VERSION ""

NS_ :

BS_:

BU_: GPS_NODE DASH

BO_ 1712 GPS_Position: 8 GPS_NODE
 SG_ lat_deg : 0|32@1- (1e-07,0) [-90|90] "deg" DASH
 SG_ lon_deg : 32|32@1- (1e-07,0) [-180|180] "deg" DASH

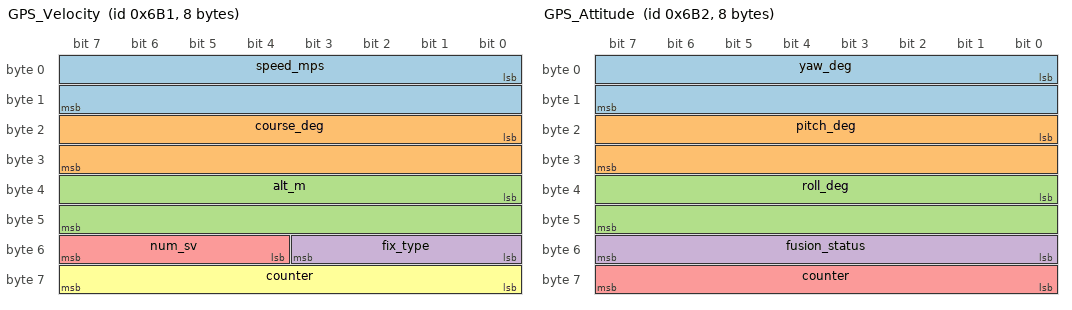
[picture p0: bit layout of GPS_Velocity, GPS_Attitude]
BO_ 1713 GPS_Velocity: 8 GPS_NODE
 SG_ speed_mps : 0|16@1+ (0.01,0) [0|655.35] "m/s" DASH
 SG_ course_deg : 16|16@1+ (0.01,0) [0|655.35] "deg" DASH
 SG_ alt_m : 32|16@1- (0.1,0) [-3276.8|3276.7] "m" DASH
 SG_ fix_type : 48|4@1+ (1,0) [0|15] "" DASH
 SG_ num_sv : 52|4@1+ (1,0) [0|15] "" DASH
 SG_ counter : 56|8@1+ (1,0) [0|255] "" DASH

BO_ 1714 GPS_Attitude: 8 GPS_NODE
 SG_ yaw_deg : 0|16@1+ (0.01,0) [0|655.35] "deg" DASH
 SG_ pitch_deg : 16|16@1- (0.01,0) [-327.68|327.67] "deg" DASH
 SG_ roll_deg : 32|16@1- (0.01,0) [-327.68|327.67] "deg" DASH
 SG_ fusion_status : 48|8@1+ (1,0) [0|255] "" DASH
 SG_ counter : 56|8@1+ (1,0) [0|255] "" DASH

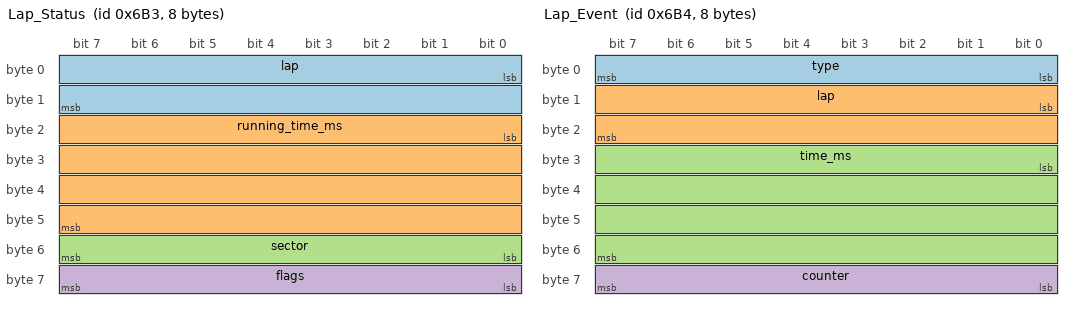
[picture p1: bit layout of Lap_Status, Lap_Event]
BO_ 1715 Lap_Status: 8 GPS_NODE
 SG_ lap : 0|16@1+ (1,0) [0|65535] "" DASH
 SG_ running_time_ms : 16|32@1+ (1,0) [0|4294967295] "ms" DASH
 SG_ sector : 48|8@1+ (1,0) [0|255] "" DASH
 SG_ flags : 56|8@1+ (1,0) [0|255] "" DASH

BO_ 1716 Lap_Event: 8 GPS_NODE
 SG_ type : 0|8@1+ (1,0) [0|255] "" DASH
 SG_ lap : 8|16@1+ (1,0) [0|65535] "" DASH
 SG_ time_ms : 24|32@1+ (1,0) [0|4294967295] "ms" DASH
 SG_ counter : 56|8@1+ (1,0) [0|255] "" DASH

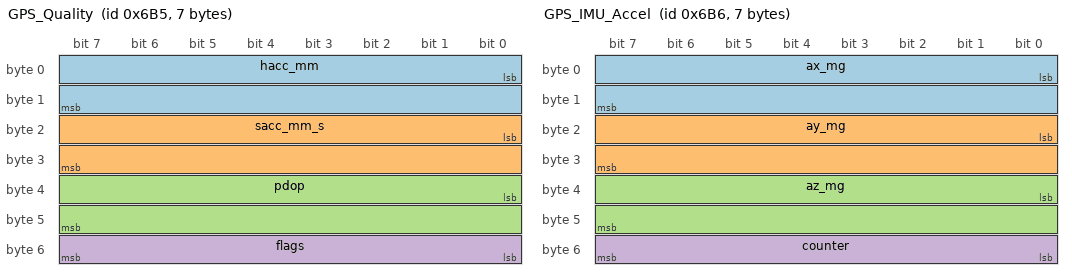
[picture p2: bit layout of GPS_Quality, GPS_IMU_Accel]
BO_ 1717 GPS_Quality: 7 GPS_NODE
 SG_ hacc_mm : 0|16@1+ (1,0) [0|65535] "mm" DASH
 SG_ sacc_mm_s : 16|16@1+ (0.1,0) [0|6553.5] "mm/s" DASH
 SG_ pdop : 32|16@1+ (0.01,0) [0|655.35] "" DASH
 SG_ flags : 48|8@1+ (1,0) [0|255] "" DASH

BO_ 1718 GPS_IMU_Accel: 7 GPS_NODE
 SG_ ax_mg : 0|16@1- (1,0) [-32768|32767] "mg" DASH
 SG_ ay_mg : 16|16@1- (1,0) [-32768|32767] "mg" DASH
 SG_ az_mg : 32|16@1- (1,0) [-32768|32767] "mg" DASH
 SG_ counter : 48|8@1+ (1,0) [0|255] "" DASH

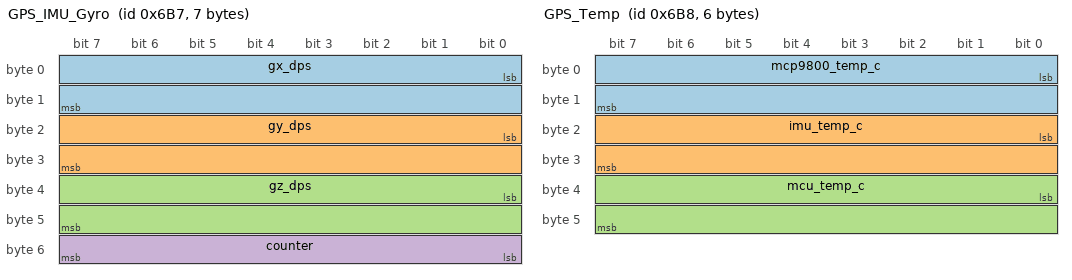
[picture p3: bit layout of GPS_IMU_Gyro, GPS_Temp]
BO_ 1719 GPS_IMU_Gyro: 7 GPS_NODE
 SG_ gx_dps : 0|16@1- (0.0625,0) [-2048|2047.94] "dps" DASH
 SG_ gy_dps : 16|16@1- (0.0625,0) [-2048|2047.94] "dps" DASH
 SG_ gz_dps : 32|16@1- (0.0625,0) [-2048|2047.94] "dps" DASH
 SG_ counter : 48|8@1+ (1,0) [0|255] "" DASH

BO_ 1720 GPS_Temp: 6 GPS_NODE
 SG_ mcp9800_temp_c : 0|16@1- (0.01,0) [-327.68|327.67] "degC" DASH
 SG_ imu_temp_c : 16|16@1- (0.01,0) [-327.68|327.67] "degC" DASH
 SG_ mcu_temp_c : 32|16@1- (0.01,0) [-327.68|327.67] "degC" DASH

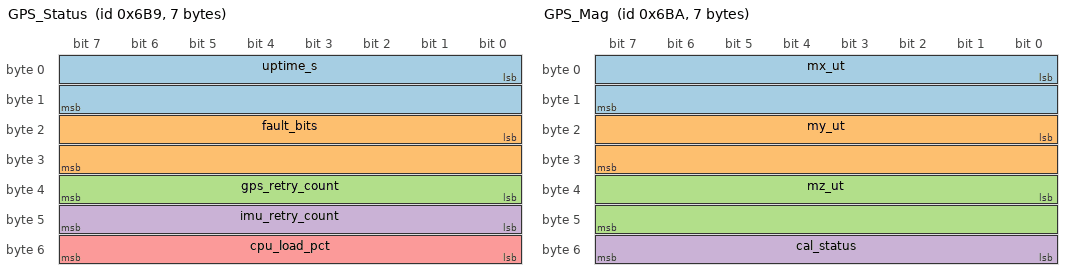
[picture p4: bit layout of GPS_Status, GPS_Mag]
BO_ 1721 GPS_Status: 7 GPS_NODE
 SG_ uptime_s : 0|16@1+ (1,0) [0|65535] "s" DASH
 SG_ fault_bits : 16|16@1+ (1,0) [0|65535] "" DASH
 SG_ gps_retry_count : 32|8@1+ (1,0) [0|255] "" DASH
 SG_ imu_retry_count : 40|8@1+ (1,0) [0|255] "" DASH
 SG_ cpu_load_pct : 48|8@1+ (1,0) [0|100] "%" DASH

BO_ 1722 GPS_Mag: 7 GPS_NODE
 SG_ mx_ut : 0|16@1- (0.1,0) [-3276.8|3276.7] "uT" DASH
 SG_ my_ut : 16|16@1- (0.1,0) [-3276.8|3276.7] "uT" DASH
 SG_ mz_ut : 32|16@1- (0.1,0) [-3276.8|3276.7] "uT" DASH
 SG_ cal_status : 48|8@1+ (1,0) [0|255] "" DASH

BO_ 1723 GPS_Frame_Origin: 8 GPS_NODE
 SG_ origin_lat_deg : 0|32@1- (1e-07,0) [-90|90] "deg" DASH
 SG_ origin_lon_deg : 32|32@1- (1e-07,0) [-180|180] "deg" DASH

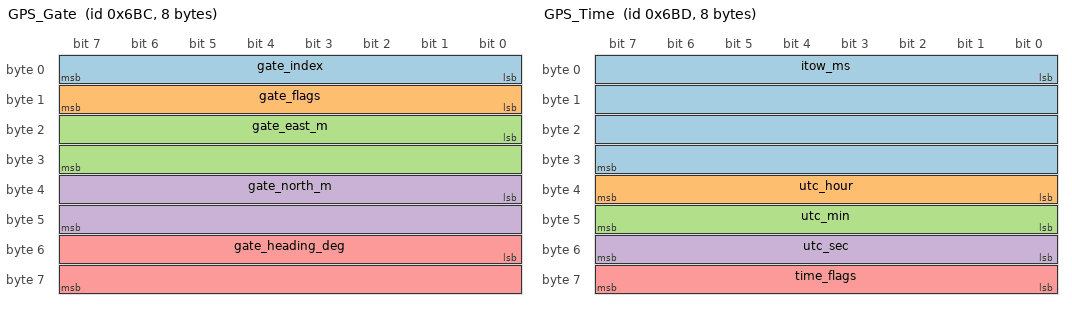
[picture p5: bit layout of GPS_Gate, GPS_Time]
BO_ 1724 GPS_Gate: 8 GPS_NODE
 SG_ gate_index : 0|8@1+ (1,0) [0|7] "" DASH
 SG_ gate_flags : 8|8@1+ (1,0) [0|255] "" DASH
 SG_ gate_east_m : 16|16@1- (0.1,0) [-3276.8|3276.7] "m" DASH
 SG_ gate_north_m : 32|16@1- (0.1,0) [-3276.8|3276.7] "m" DASH
 SG_ gate_heading_deg : 48|16@1+ (0.1,0) [0|6553.5] "deg" DASH

BO_ 1725 GPS_Time: 8 GPS_NODE
 SG_ itow_ms : 0|32@1+ (1,0) [0|604799999] "ms" DASH
 SG_ utc_hour : 32|8@1+ (1,0) [0|23] "h" DASH
 SG_ utc_min : 40|8@1+ (1,0) [0|59] "min" DASH
 SG_ utc_sec : 48|8@1+ (1,0) [0|60] "s" DASH
 SG_ time_flags : 56|8@1+ (1,0) [0|255] "" DASH

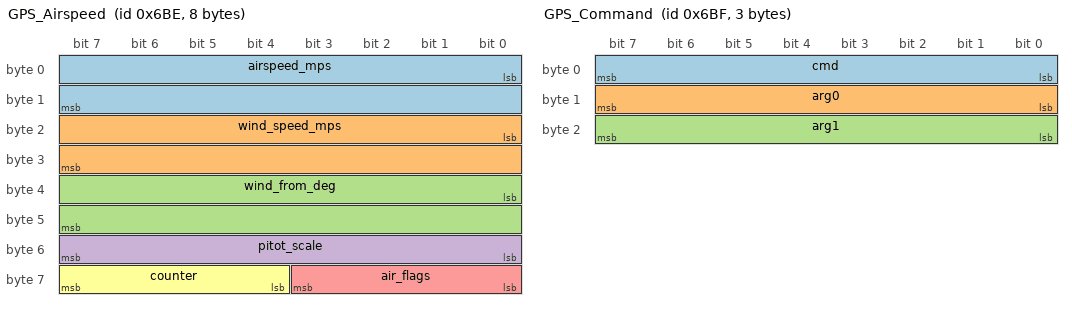
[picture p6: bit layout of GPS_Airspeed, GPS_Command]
BO_ 1726 GPS_Airspeed: 8 GPS_NODE
 SG_ airspeed_mps : 0|16@1+ (0.01,0) [0|655.35] "m/s" DASH
 SG_ wind_speed_mps : 16|16@1+ (0.01,0) [0|655.35] "m/s" DASH
 SG_ wind_from_deg : 32|16@1+ (0.1,0) [0|360] "deg" DASH
 SG_ pitot_scale : 48|8@1+ (0.004,0.5) [0.5|1.52] "" DASH
 SG_ air_flags : 56|4@1+ (1,0) [0|15] "" DASH
 SG_ counter : 60|4@1+ (1,0) [0|15] "" DASH

BO_ 1727 GPS_Command: 3 DASH
 SG_ cmd : 0|8@1+ (1,0) [0|255] "" GPS_NODE
 SG_ arg0 : 8|8@1+ (1,0) [0|255] "" GPS_NODE
 SG_ arg1 : 16|8@1+ (1,0) [0|255] "" GPS_NODE

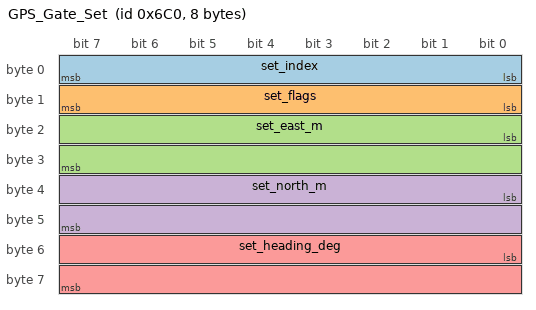
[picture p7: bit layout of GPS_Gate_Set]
BO_ 1728 GPS_Gate_Set: 8 DASH
 SG_ set_index : 0|8@1+ (1,0) [0|255] "" GPS_NODE
 SG_ set_flags : 8|8@1+ (1,0) [0|255] "" GPS_NODE
 SG_ set_east_m : 16|16@1- (0.1,0) [-3276.8|3276.7] "m" GPS_NODE
 SG_ set_north_m : 32|16@1- (0.1,0) [-3276.8|3276.7] "m" GPS_NODE
 SG_ set_heading_deg : 48|16@1+ (0.1,0) [0|359.9] "deg" GPS_NODE

CM_ BO_ 1712 "50 Hz fused position from the KF (lat/lon). The GNSS fixes are 20 Hz; between them the estimate is carried forward by the IMU.";
CM_ BO_ 1713 "50 Hz fused speed/course/altitude and fix quality summary.";
CM_ SG_ 1713 fix_type "UBX-NAV-PVT fixType (2 = 2D, 3 = 3D, 4 = GNSS+DR), forced to 0 whenever the receiver's gnssFixOK flag is clear or no NAV-PVT has arrived for 1 s.";
CM_ BO_ 1714 "50 Hz Mahony AHRS Euler output (yaw/pitch/roll).";
CM_ SG_ 1714 fusion_status "What the estimate is built from (CAN_FUSION_STATUS_* in can_defs.h): bit0 IMU samples flowing, bit1 magnetometer responding, bit2 mag calibrated (yaw is a usable heading), bit3 ENU origin set, bit4 GPS-aided (a valid fix within the last 1 s; clear = dead reckoning), bit5 time locked to GPS by PPS.";
CM_ BO_ 1715 "10 Hz lap timer status.";
CM_ SG_ 1715 lap "Laps completed since the start/finish gate was last set or cleared.";
CM_ SG_ 1715 flags "CAN_LAP_FLAG_* in can_defs.h: bit0 running (a lap is being timed), bit1 armed (start/finish gate placed), bit2 degraded (no recent GPS fix or no GPS time lock - crossings are not being timed reliably).";
CM_ BO_ 1716 "Lap/sector/TM2 event, sent on occurrence (not periodic).";
CM_ SG_ 1716 type "0=lap complete, 1=sector crossed, 2=TM2 time-mark; see CAN_LAP_EVENT_* in can_defs.h.";
CM_ SG_ 1716 lap "LAP: number of the lap just completed (1 = first). SECTOR: laps completed before the lap that sector belongs to (so one less than that lap's LAP event). TM2: 0.";
CM_ SG_ 1716 time_ms "Meaning depends on type: lap time, sector time, or GPS iTOW for a TM2 mark.";
CM_ BO_ 1717 "5 Hz GNSS accuracy/DOP/RTK summary.";
CM_ SG_ 1717 flags "bit0 gnssFixOK, bits1-2 carrSoln (0 none/1 float/2 fixed), bit3 diffSoln.";
CM_ BO_ 1718 "100 Hz calibrated body-frame accelerometer, +-16 g FS.";
CM_ BO_ 1719 "100 Hz calibrated body-frame gyroscope. 0.0625 dps/LSB, range +-2048 dps, covering the LSM6DSO32's +-2000 dps FS with margin.";
CM_ BO_ 1720 "1 Hz temperature summary: MCP9800 board ambient, IMU die temp, MCU internal temp (whole degrees). A sensor that fails to read keeps its last good value.";
CM_ BO_ 1721 "1 Hz node health: uptime, fault bits, retry counters, CPU load.";
CM_ SG_ 1721 fault_bits "The node's whole status event group (SYS_EVT_* in sys/app.h), not faults alone: bit0 GPS ready (valid fix), bit1 IMU ready, bit2 mag ready, bit3 time locked (PPS), bit4 ENU origin set, bit5 GPS fault (no NAV-PVT stream), bit6 IMU fault, bit7 mag fault, bit8 flash unsaved (a gate/cal change is not in flash yet; written when the car is next stationary), bit9 flash write failed, bit10 flash tidy-up waiting for the car to be stationary.";
CM_ SG_ 1721 gps_retry_count "GPS link recoveries since boot (UART re-arms + receiver re-configurations), saturating at 255.";
CM_ SG_ 1721 imu_retry_count "Failed IMU reads since boot, saturating at 255.";
CM_ SG_ 1721 uptime_s "Seconds since boot, saturating at 65535 (~18.2 h).";
CM_ BO_ 1722 "10 Hz raw magnetometer, diagnostic only (not fed into AHRS directly). Units are uT*10, not raw sensor LSB, so the frame is self-describing.";
CM_ SG_ 1722 cal_status "Continuous background calibration state: 0 uncalibrated, 1 collecting (candidate, still sweeping the heading circle), 2 calibrated (coverage good), 3 validated (also agrees with GPS course-over-ground).";
CM_ BO_ 1723 "1 Hz ENU frame origin (absolute lat/lon). The gates and the node's own ENU are relative to this; re-anchored at each power-up's first fix, so the dash must re-read it rather than assume it's fixed.";
CM_ BO_ 1724 "Lap gate, one slot per frame round-robined (~5 Hz aggregate, whole set in ~1.6 s). Position is ENU metres relative to GPS_Frame_Origin. index 0 = start/finish, 1-7 = sectors; gate_flags bit0 = valid (0 => empty/cleared slot).";
CM_ SG_ 1724 gate_index "Which gate slot this frame carries (plain data field, not a multiplexor).";
CM_ SG_ 1724 gate_heading_deg "Direction of travel through the gate as an ENU math angle: degrees anticlockwise from EAST (atan2(north, east)), not a compass bearing. 0 = east, 90 = north.";
CM_ SG_ 1724 gate_flags "bit0 = valid; a cleared slot is broadcast with valid=0 so the dash removes it.";
CM_ BO_ 1725 "1 Hz GPS time reference for other nodes: iTOW (same time domain as Lap_Event TM2 marks) plus UTC wall clock. UTC date is not carried (the MoTeC gets it via NMEA RMC); note GPS time leads UTC by the leap-second count, so UTC h/m/s is not simply iTOW mod 1 day.";
CM_ SG_ 1725 time_flags "bit0 = UTC time valid (NAV-PVT validTime), bit1 = fully resolved (no sub-second ambiguity).";
CM_ BO_ 1726 "10 Hz pitot airspeed and the wind estimated from it against the GPS ground velocity (fusion/airdata.c). Logging/analysis only: not used for position or lap timing. Source: EvoScann P4-A on 0x190, CH3 = total pressure, static = mean of CH1, CH2, CH4.";
CM_ SG_ 1726 airspeed_mps "True airspeed: Bernoulli on the tared dynamic pressure, divided by pitot_scale. 0 until the first standstill tare, or with no pitot frames.";
CM_ SG_ 1726 wind_from_deg "Compass direction the wind blows FROM (0 = north, 90 = east).";
CM_ SG_ 1726 pitot_scale "Estimated installation factor k: the pitot reads k x the true airspeed.";
CM_ SG_ 1726 air_flags "CAN_GPS_AIR_FLAG_*: bit0 pitot frames arriving, bit1 tared at a standstill, bit2 wind + scale converged, bit3 density from the sensor temperature (else 20 C assumed).";
CM_ SG_ 1726 counter "4-bit rolling counter.";
CM_ BO_ 1727 "RX only: host/dash sends commands to the GPS node. byte0=cmd, byte1=arg0, byte2=arg1; see CAN_CMD_* in can_defs.h.";
CM_ SG_ 1727 cmd "0x01 GATE_SET (arg0=slot 0-7, or 0xFE=next free sector slot), 0x02 GATE_CLEAR (arg0=slot,0xFF=all), 0x10 MAG_CAL_START (discard the mag cal and re-sweep), 0x11 MAG_CAL_STOP (no effect), 0x20 CONFIG_SAVE (compact the flash store when next stationary), 0x30 NMEA_CFG (arg0=rate Hz 1-20 or 0=keep, arg1=enable).";
CM_ BO_ 1728 "RX only: place a lap gate at a given position rather than at the car. Same layout as GPS_Gate. Position is ENU metres relative to the node's CURRENT GPS_Frame_Origin; ignored until the node has an origin. Saved to flash and broadcast on GPS_Gate like a gate set from the car.";
CM_ SG_ 1728 set_index "Slot: 0 = start/finish (clears the sector gates), 1-7 = sector, 0xFE = next free sector slot.";
CM_ SG_ 1728 set_flags "Reserved, send 0.";
CM_ SG_ 1728 set_heading_deg "Direction of travel through the gate, degrees anticlockwise from east, as GPS_Gate.";
